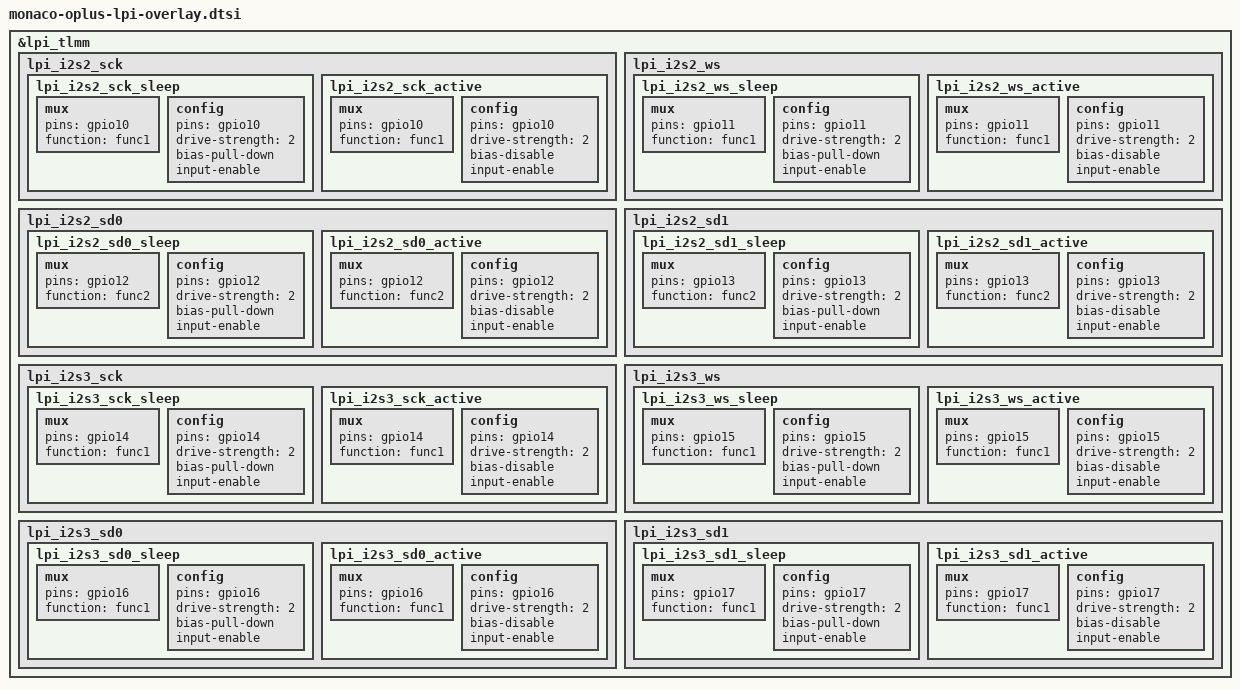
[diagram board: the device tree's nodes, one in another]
//From:


&lpi_tlmm {
    lpi_i2s2_sck {
        lpi_i2s2_sck_sleep: lpi_i2s2_sck_sleep {
            mux {
                pins = "gpio10";
                function = "func1";
            };

            config {
                pins = "gpio10";
                drive-strength = <2>;   /* 2 mA */
                bias-pull-down;         /* PULL DOWN */
                input-enable;
            };
        };

        lpi_i2s2_sck_active: lpi_i2s2_sck_active {
            mux {
                pins = "gpio10";
                function = "func1";
            };

            config {
                pins = "gpio10";
                drive-strength = <2>;   /* 2 mA */
                bias-disable;           /* NO PULL */
                input-enable;
            };
        };
    };

    lpi_i2s2_ws {
        lpi_i2s2_ws_sleep: lpi_i2s2_ws_sleep {
            mux {
                pins = "gpio11";
                function = "func1";
            };

            config {
                pins = "gpio11";
                drive-strength = <2>;   /* 2 mA */
                bias-pull-down;         /* PULL DOWN */
                input-enable;
            };
        };

        lpi_i2s2_ws_active: lpi_i2s2_ws_active {
            mux {
                pins = "gpio11";
                function = "func1";
            };

            config {
                pins = "gpio11";
                drive-strength = <2>;   /* 2 mA */
                bias-disable;           /* NO PULL */
                input-enable;
            };
        };
    };

    lpi_i2s2_sd0 {
        lpi_i2s2_sd0_sleep: lpi_i2s2_sd0_sleep {
            mux {
                pins = "gpio12";
                function = "func2";
            };

            config {
                pins = "gpio12";
                drive-strength = <2>;   /* 2 mA */
                bias-pull-down;         /* PULL DOWN */
                input-enable;
            };
        };

        lpi_i2s2_sd0_active: lpi_i2s2_sd0_active {
            mux {
                pins = "gpio12";
                function = "func2";
            };

            config {
                pins = "gpio12";
                drive-strength = <2>;   /* 2 mA */
                bias-disable;           /* NO PULL */
                input-enable;
            };
        };
    };

    lpi_i2s2_sd1 {
        lpi_i2s2_sd1_sleep: lpi_i2s2_sd1_sleep {
            mux {
                pins = "gpio13";
                function = "func2";
            };

            config {
                pins = "gpio13";
                drive-strength = <2>;   /* 2 mA */
                bias-pull-down;         /* PULL DOWN */
                input-enable;
            };
        };

        lpi_i2s2_sd1_active: lpi_i2s2_sd1_active {
            mux {
                pins = "gpio13";
                function = "func2";
            };

            config {
                pins = "gpio13";
                drive-strength = <2>;   /* 2 mA */
                bias-disable;           /* NO PULL */
                input-enable;
            };
        };
    };

    lpi_i2s3_sck {
        lpi_i2s3_sck_sleep: lpi_i2s3_sck_sleep {
            mux {
                pins = "gpio14";
                function = "func1";
            };

            config {
                pins = "gpio14";
                drive-strength = <2>;   /* 2 mA */
                bias-pull-down;         /* PULL DOWN */
                input-enable;
            };
        };

        lpi_i2s3_sck_active: lpi_i2s3_sck_active {
            mux {
                pins = "gpio14";
                function = "func1";
            };

            config {
                pins = "gpio14";
                drive-strength = <2>;   /* 2 mA */
                bias-disable;           /* NO PULL */
                input-enable;
            };
        };
    };

    lpi_i2s3_ws {
        lpi_i2s3_ws_sleep: lpi_i2s3_ws_sleep {
            mux {
                pins = "gpio15";
                function = "func1";
            };

            config {
                pins = "gpio15";
                drive-strength = <2>;   /* 2 mA */
                bias-pull-down;         /* PULL DOWN */
                input-enable;
            };
        };

        lpi_i2s3_ws_active: lpi_i2s3_ws_active {
            mux {
                pins = "gpio15";
                function = "func1";
            };

            config {
                pins = "gpio15";
                drive-strength = <2>;   /* 2 mA */
                bias-disable;           /* NO PULL */
                input-enable;
            };
        };
    };

    lpi_i2s3_sd0 {
        lpi_i2s3_sd0_sleep: lpi_i2s3_sd0_sleep {
            mux {
                pins = "gpio16";
                function = "func1";
            };

            config {
                pins = "gpio16";
                drive-strength = <2>;   /* 2 mA */
                bias-pull-down;         /* PULL DOWN */
                input-enable;
            };
        };

        lpi_i2s3_sd0_active: lpi_i2s3_sd0_active {
            mux {
                pins = "gpio16";
                function = "func1";
            };

            config {
                pins = "gpio16";
                drive-strength = <2>;   /* 2 mA */
                bias-disable;           /* NO PULL */
                input-enable;
            };
        };
    };

    lpi_i2s3_sd1 {
        lpi_i2s3_sd1_sleep: lpi_i2s3_sd1_sleep {
            mux {
                pins = "gpio17";
                function = "func1";
            };

            config {
                pins = "gpio17";
                drive-strength = <2>;   /* 2 mA */
                bias-pull-down;         /* PULL DOWN */
                input-enable;
            };
        };

        lpi_i2s3_sd1_active: lpi_i2s3_sd1_active {
            mux {
                pins = "gpio17";
                function = "func1";
            };

            config {
                pins = "gpio17";
                drive-strength = <2>;   /* 2 mA */
                bias-disable;           /* NO PULL */
                input-enable;
            };
        };
    };
};
